# nrf54h20_engb_sysctrl register map
Vendor: Nordic Semiconductor; Series: nRF54h; File version: 1
Registers are 32-bit, read-write, reset 0x0 unless marked. A register's access mark holds for its fields unless they carry their own. Offsets are from the block's base; [hi:lo] are bit positions; lines under a group give offsets from that group; {n}, {i} and the like mark numbered series; 'fields as' and 'values as' point back to an identical list.

## OICR — One time programmable Information Configuration Registers
Base 0x2F840000
0x00 DEVICE group — Unspecified
  {0x0+4j} UUID[{j}] (j=0..3) rw-once reset 0xFFFFFFFF — Description collection: 128-bit Universally Unique IDentifier (UUID).
    [31:0] UUID — Device UUID [n].
  0x10 TYPE rw-once reset 0xFFFFFFFF — Device type.
    [31:0] TYPE
      0=Die (Device is a physical DIE.); 0xFFFFFFFF=FPGA (Device is a FPGA.)
  {0x14+4j} TESTIMPRINT[{j}] (j=0..7) rw-once reset 0xFFFFFFFF — Description collection: Production test imprint.
    [31:0] TESTIMPRINT — Production test imprint.
  0x34 PARTNO ro reset 0xFFFFFFFF — Part number.
    [31:0] PART
  0x38 HWREVISION ro reset 0xFFFFFFFF — Hardware revision.
    [31:0] HWREVISION — Hardvare revision.
  0x3C PRODUCTIONREVISION ro reset 0xFFFFFFFF — Production reversion.
0x40 PUF group — Unspecified
  0x00 STATUS rw-once reset 0xFFFFFFFF — PUF enrollment status
    [31:0] STATUS — PUF enrollment status.
      0x50FA50FA=Enrolled (PUF enrollment has been completed.); 0xFFFFFFFF=NotEnrolled (PUF enrollment has not been done.)
0x50 PRECALIB group — Unspecified
  0x00 PRECALIBRDY rw-once reset 0xFFFFFFFF — PRECALIB information is populated and ready.
    [3:0] PRECALIBRDY
      0=Ready (Precalibration information is populated and ready.); 15=NotReady (Precalibration information is not populated or ready.)
  {0x4+4j} ADDRESS[{j}] (j=0..63) rw-once reset 0xFFFFFFFF — Description collection: Address to trim register
  {0x104+4j} DATA[{j}] (j=0..63) rw-once reset 0xFFFFFFFF — Description collection: Data for trim register
{0x260+0x4C*i} MRAM[{i}] (i=0..1) group — Unspecified
  0x00 TRIMRDY rw-once reset 0xFFFFFFFF — Description cluster: MRAM TRIM information is populated and ready.
    [0] TRIMRDY — MRAM TRIM information is populated and ready.
      0=Ready (Trim information is populated and ready.); 1=NotReady (Trim information is not populated or ready.)
  0x04 LOWAVGCURR group — Unspecified
    0x00 READ rw-once reset 0xFFFFFFFF — Description cluster: Timeout value for low average current in case of read.
      [31:0] VALUE
    0x04 WRITE rw-once reset 0xFFFFFFFF — Description cluster: Timeout value for low average current in case of write.
      [31:0] VALUE
    0x08 ERASE rw-once reset 0xFFFFFFFF — Description cluster: Timeout value for low average current in case of erase.
      [31:0] VALUE
  0x10 WAITSTATES rw-once reset 0xFFFFFFFF — Description cluster: Default MRAM[n] waitstates.
    [31:0] VALUE
  0x14 READYNEXTTIMEOUT rw-once reset 0xFFFFFFFF — Description cluster: Default MRAM[n] READYNEXTTIMEOUT.
    [31:0] VALUE
  0x18 NCONFIG rw-once reset 0xFFFFFFFF — Description cluster: Number of bits to load from trim configuration for MRAM[n].
    [31:0] VALUE
  {0x1C+4j} CONFIG[{j}] (j=0..11) rw-once reset 0xFFFFFFFF — Description collection: MRAM[n] trim configuration.
    [31:0] CONFIG — Trim Configuration [o].
0x300 UROT group — Unspecified
  {0x0+4j} DATA[{j}] (j=0..63) reset 0xFFFFFFFF — Description collection: Reserved for updatable RoT data.
    [31:0] DATA
0x400 USER group — Unspecified
  0x00 ROT group — Assets installed to establish initial Root of Trust in the device.
    {0x0+0x28*k} UROTPUBKEY[{k}] (k=0..2) group — Unspecified
      {0x0+4l} DIGEST[{l}] (l=0..7) rw-once reset 0xFFFFFFFF — Description collection: First 256 bits of SHA2-512 digest over RoT public key generation [n].
        [31:0] VALUE — Value for word [o] in the key digest [n].
      {0x20+4l} REVOKE[{l}] (l=0..1) rw-once reset 0xFFFFFFFF — Description collection: Revocation status for public key generation [n].
        [31:0] STATUS — Revocation status.
          0xFFFFFFFF=NotRevoked (Key not revoked.)
    {0x78+0x28*k} RECOVERYPUBKEY[{k}] (k=0..2) group — Unspecified
      {0x0+4l} DIGEST[{l}] (l=0..7) rw-once reset 0xFFFFFFFF — Description collection: First 256 bits of SHA2-512 digest over RoT public key generation [n].
        [31:0] VALUE — Value for word [o] in the key digest [n].
      {0x20+4l} REVOKE[{l}] (l=0..1) rw-once reset 0xFFFFFFFF — Description collection: Revocation status for public key generation [n].
        fields as USER.ROT.UROTPUBKEY[0].REVOKE[0]
    {0xF0+0x28*k} AUTHOPKEY[{k}] (k=0..2) group — Unspecified
      {0x0+4l} DIGEST[{l}] (l=0..7) rw-once reset 0xFFFFFFFF — Description collection: First 256 bits of SHA2-512 digest over RoT authenticated operation public key generation [n].
        [31:0] VALUE — Value for word [o] in the key digest [n].
      {0x20+4l} REVOKE[{l}] (l=0..1) rw-once reset 0xFFFFFFFF — Description collection: Revocation status for RoT authenticated operation public key generation [n].
        fields as USER.ROT.UROTPUBKEY[0].REVOKE[0]
    {0x168+0x28*k} AUTHDEBUGKEY[{k}] (k=0..2) group — Unspecified
      {0x0+4l} DIGEST[{l}] (l=0..7) rw-once reset 0xFFFFFFFF — Description collection: First 256 bits of SHA2-512 digest over RoT authenticated debug public key generation [n].
        [31:0] VALUE — Value for word [o] in the key digest [n].
      {0x20+4l} REVOKE[{l}] (l=0..1) rw-once reset 0xFFFFFFFF — Description collection: Revocation status for RoT authenticated debug public key generation [n].
        fields as USER.ROT.UROTPUBKEY[0].REVOKE[0]
    0x1E0 FWENC group — Unspecified
      {0x0+0x20*l} AES256[{l}] (l=0..1) group — Unspecified
        {0x0+4m} VALUE[{m}] (m=0..7) rw-once reset 0xFFFFFFFF — Description collection: RoT AES256 firmware encryption key generation [n].
          [31:0] VALUE — Value for word [o] in the key value [n].
      {0x40+0x10*l} SM4[{l}] (l=0..3) group — Unspecified
        {0x0+4m} VALUE[{m}] (m=0..3) rw-once reset 0xFFFFFFFF — Description collection: RoT SM4 firmware encryption key generation [n].
          [31:0] VALUE — Value for word [o] in the key value [n].
      {0x80+0x20*l} UROTENC[{l}] (l=0..1) group — Unspecified
        {0x0+4m} VALUE[{m}] (m=0..7) rw-once reset 0xFFFFFFFF — Description collection: AES256 key for decryption of UROT firmware.
          [31:0] VALUE — Value for word [o] in the key value [n].
    0x2A0 KEYID rw-once reset 0xFFFFFFFF — Root of trust key identifier.
      [31:0] VALUE
        0xFFFFFFFF=Unspecified
  0x2A4 POLICY group — ROM enforced device policy
    {0x0+4k} RFU[{k}] (k=0..7) rw-once reset 0xFFFFFFFF — Description collection:
0x700 NORDIC group — Unspecified
  0x00 ROT group — Assets installed to establish initial Root of Trust in the device.
    {0x0+0x28*k} UROTPUBKEY[{k}] (k=0..2) group — Unspecified
      {0x0+4l} DIGEST[{l}] (l=0..7) rw-once reset 0xFFFFFFFF — Description collection: First 256 bits of SHA2-512 digest over RoT public key generation [n].
        [31:0] VALUE — Value for word [o] in the key digest [n].
      {0x20+4l} REVOKE[{l}] (l=0..1) rw-once reset 0xFFFFFFFF — Description collection: Revocation status for public key generation [n].
        fields as USER.ROT.UROTPUBKEY[0].REVOKE[0]
    {0x78+0x28*k} RECOVERYPUBKEY[{k}] (k=0..2) group — Unspecified
      {0x0+4l} DIGEST[{l}] (l=0..7) rw-once reset 0xFFFFFFFF — Description collection: First 256 bits of SHA2-512 digest over RoT public key generation [n].
        [31:0] VALUE — Value for word [o] in the key digest [n].
      {0x20+4l} REVOKE[{l}] (l=0..1) rw-once reset 0xFFFFFFFF — Description collection: Revocation status for public key generation [n].
        fields as USER.ROT.UROTPUBKEY[0].REVOKE[0]
    {0xF0+0x28*k} AUTHOPKEY[{k}] (k=0..2) group — Unspecified
      {0x0+4l} DIGEST[{l}] (l=0..7) rw-once reset 0xFFFFFFFF — Description collection: First 256 bits of SHA2-512 digest over RoT authenticated operation public key generation [n].
        [31:0] VALUE — Value for word [o] in the key digest [n].
      {0x20+4l} REVOKE[{l}] (l=0..1) rw-once reset 0xFFFFFFFF — Description collection: Revocation status for RoT authenticated operation public key generation [n].
        fields as USER.ROT.UROTPUBKEY[0].REVOKE[0]
    {0x168+0x28*k} AUTHDEBUGKEY[{k}] (k=0..2) group — Unspecified
      {0x0+4l} DIGEST[{l}] (l=0..7) rw-once reset 0xFFFFFFFF — Description collection: First 256 bits of SHA2-512 digest over RoT authenticated debug public key generation [n].
        [31:0] VALUE — Value for word [o] in the key digest [n].
      {0x20+4l} REVOKE[{l}] (l=0..1) rw-once reset 0xFFFFFFFF — Description collection: Revocation status for RoT authenticated debug public key generation [n].
        fields as USER.ROT.UROTPUBKEY[0].REVOKE[0]
    0x1E0 FWENC group — Unspecified
      {0x0+0x20*l} AES256[{l}] (l=0..1) group — Unspecified
        {0x0+4m} VALUE[{m}] (m=0..7) rw-once reset 0xFFFFFFFF — Description collection: RoT AES256 firmware encryption key generation [n].
          [31:0] VALUE — Value for word [o] in the key value [n].
      {0x40+0x10*l} SM4[{l}] (l=0..3) group — Unspecified
        {0x0+4m} VALUE[{m}] (m=0..3) rw-once reset 0xFFFFFFFF — Description collection: RoT SM4 firmware encryption key generation [n].
          [31:0] VALUE — Value for word [o] in the key value [n].
      {0x80+0x20*l} UROTENC[{l}] (l=0..1) group — Unspecified
        {0x0+4m} VALUE[{m}] (m=0..7) rw-once reset 0xFFFFFFFF — Description collection: AES256 key for decryption of UROT firmware.
          [31:0] VALUE — Value for word [o] in the key value [n].
    0x2A0 KEYID rw-once reset 0xFFFFFFFF — Root of trust key identifier.
      [31:0] VALUE
        0xFFFFFFFF=Unspecified
  0x2A4 LCS group — Unspecified
    {0x0+4k} FFF[{k}] (k=0..2) rw-once reset 0xFFFFFFFF — Description collection: Life cycle state FFF encoding.
    {0xC+4k} DISCARDED[{k}] (k=0..2) rw-once reset 0xFFFFFFFF — Description collection: Life cycle state DISCARDED encoding.
    {0x18+4k} ANALYSIS[{k}] (k=0..2) rw-once reset 0xFFFFFFFF — Description collection: Life cycle state ANALYSIS encoding.
  0x2C8 POLICY group — ROM enforced device policy
    0x00 ERASEONEMPTY rw-once reset 0xFFFFFFFF — Policy to disable erasing of MRAMC111 memory on backward transition to LCS EMPTY.
      [31:0] CONFIG — Policy configuration
        0x72B4E5AC=DISABLE (Disable erasing MRAMC111 on backward transition to EMPTY.)
    {0x4+4k} RFU[{k}] (k=0..8) rw-once reset 0xFFFFFFFF — Description collection:
0xA00 PICR group — Product (paper-spin) Information Configuration Registers
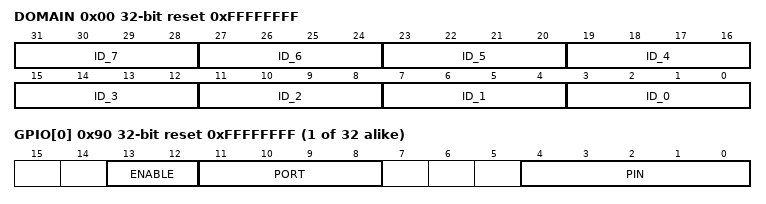
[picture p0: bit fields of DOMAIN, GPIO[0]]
  0x00 DOMAIN reset 0xFFFFFFFF — Block use of a domain
    [all] fields
      15=NotBlocked (Domain not blocked)
    [4n+3:4n] ID_{n} (n=0..7) — Domain identifier of the domain to be blocked
  {0x10+8j} MEM[{j}] (j=0..7) group — Unspecified
    0x00 ADDR reset 0xFFFFFFFF — Description cluster: Start address of the memory to be blocked
      [31:0] ADDR — Memory start address
        0xFFFFFFFF=NotBlocked (Memory not blocked)
    0x04 SIZE reset 0xFFFFFFFF — Description cluster: Size of the memory to be blocked
      [31:0] SIZE — Memory size in bytes
  {0x50+8j} PERIPH[{j}] (j=0..7) group — Unspecified
    0x00 ADDR reset 0xFFFFFFFF — Description cluster: Start address of the peripheral to be blocked
      [31:0] ADDR — Peripheral start address
        0xFFFFFFFF=NotBlocked (Peripheral not blocked)
    0x04 SIZE reset 0xFFFFFFFF — Description cluster: Number of peripherals to be blocked
      [31:0] SIZE — Peripheral size in 4Kbytes.
  {0x90+4j} GPIO[{j}] (j=0..31) reset 0xFFFFFFFF — Description collection: GPIO configuration to block a pin or port
    [13:12] ENABLE — Enable blocking
      0=PinBlock (GPIO pin block is enabled); 2=PortBlock (Enable blocking a whole port); 3=Disabled (GPIO pin block is disabled)
    [11:8] PORT — Port number
    [4:0] PIN — Pin number
0xC00 FWPATCH group — Unspecified
  0x00 SYSCTRL group — Unspecified
    {0x0+4k} PATCHADDR[{k}] (k=0..7) rw-once reset 0xFFFFFFFF — Description collection: Patch address for SysCtrl ROM patch entry point n.
      [31:0] ADDR — Address
    {0x20+4k} TRAPADDR[{k}] (k=0..7) rw-once reset 0xFFFFFFFF — Description collection: Addresses in SysCtrl ROM which will be trapped to the PATCHADDR target.
      [31:0] ADDR — Address
  0x40 SECROM group — Unspecified
    {0x0+4k} PATCHADDR[{k}] (k=0..223) rw-once reset 0xFFFFFFFF — Description collection: Patch address for secure domain ROM patch entry point n.
      [31:0] ADDR — Address
  {0x3C0+4j} PATCHCODE[{j}] (j=0..3087) rw-once reset 0xFFFFFFFF — Description collection: Patch code area. The code area is shared through mutual agreement between SysCtrl ROM and Secure Domain ROM.
    [31:0] DATA

## Notices in the file
Copyright (c) 2010 - 2024, Nordic Semiconductor ASA
All rights reserved.
Redistribution and use in source and binary forms, with or without modification,
are permitted provided that the following conditions are met:
1. Redistributions of source code must retain the above copyright notice, this
list of conditions and the following disclaimer.
2. Redistributions in binary form, except as embedded into a Nordic
Semiconductor ASA integrated circuit in a product or a software update for
such product, must reproduce the above copyright notice, this list of
conditions and the following disclaimer in the documentation and/or other
materials provided with the distribution.
3. Neither the name of Nordic Semiconductor ASA nor the names of its
contributors may be used to endorse or promote products derived from this
software without specific prior written permission.
4. This software, with or without modification, must only be used with a
Nordic Semiconductor ASA integrated circuit.
5. Any software provided in binary form under this license must not be reverse
engineered, decompiled, modified and/or disassembled.
THIS SOFTWARE IS PROVIDED BY NORDIC SEMICONDUCTOR ASA "AS IS" AND ANY EXPRESS
OR IMPLIED WARRANTIES, INCLUDING, BUT NOT LIMITED TO, THE IMPLIED WARRANTIES
OF MERCHANTABILITY, NONINFRINGEMENT, AND FITNESS FOR A PARTICULAR PURPOSE ARE
DISCLAIMED. IN NO EVENT SHALL NORDIC SEMICONDUCTOR ASA OR CONTRIBUTORS BE
LIABLE FOR ANY DIRECT, INDIRECT, INCIDENTAL, SPECIAL, EXEMPLARY, OR
CONSEQUENTIAL DAMAGES (INCLUDING, BUT NOT LIMITED TO, PROCUREMENT OF SUBSTITUTE
GOODS OR SERVICES; LOSS OF USE, DATA, OR PROFITS; OR BUSINESS INTERRUPTION)
HOWEVER CAUSED AND ON ANY THEORY OF LIABILITY, WHETHER IN CONTRACT, STRICT
LIABILITY, OR TORT (INCLUDING NEGLIGENCE OR OTHERWISE) ARISING IN ANY WAY OUT
OF THE USE OF THIS SOFTWARE, EVEN IF ADVISED OF THE POSSIBILITY OF SUCH DAMAGE.
